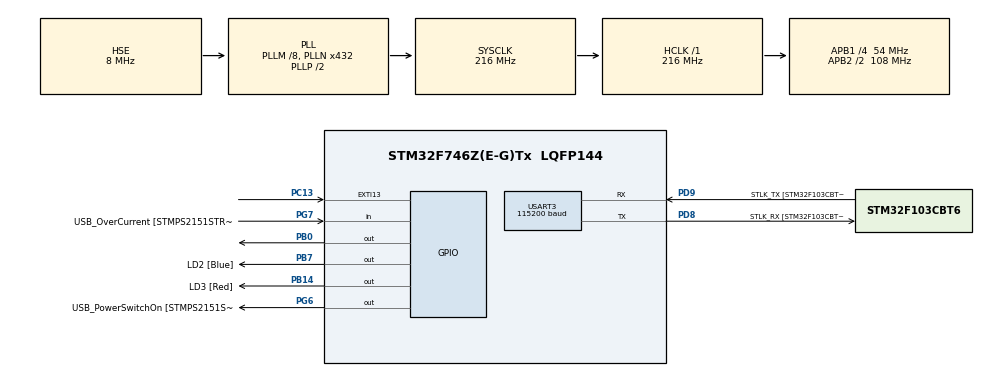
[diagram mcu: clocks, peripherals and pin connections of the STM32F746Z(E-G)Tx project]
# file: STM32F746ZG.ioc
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Mcu.Family=STM32F7
Mcu.Name=STM32F746Z(E-G)Tx
Mcu.Package=LQFP144
NVIC.EXTI15_10_IRQn=true\:3\:3\:true
NVIC.PriorityGroup=NVIC_PRIORITYGROUP_2
NVIC.USART3_IRQn=true\:0\:0\:false
PA1.GPIO_Label=RMII_REF_CK [LAN8742A-CZ-TR_REFCLK0]
PA1.Signal=ETH_REF_CLK
PA10.GPIO_Label=USB_ID
PA10.Signal=USB_OTG_FS_ID
PA11.GPIO_Label=USB_DM
PA11.Signal=USB_OTG_FS_DM
PA12.GPIO_Label=USB_DP
PA12.Signal=USB_OTG_FS_DP
PA13.GPIO_Label=TMS
PA13.Mode=Trace-Asynchronous_SW
PA13.Signal=SYS_JTMS-SWDIO
PA14.GPIO_Label=TCK
PA14.Mode=Trace-Asynchronous_SW
PA14.Signal=SYS_JTCK-SWCLK
PA2.GPIO_Label=RMII_MDIO [LAN8742A-CZ-TR_MDIO]
PA2.Signal=ETH_MDIO
PA7.GPIO_Label=RMII_CRS_DV [LAN8742A-CZ-TR_CRS_DV]
PA7.Signal=ETH_CRS_DV
PA8.GPIO_Label=USB_SOF [TP1]
PA8.Signal=USB_OTG_FS_SOF
PA9.GPIO_Label=USB_VBUS
PA9.Signal=USB_OTG_FS_VBUS
PB0.Signal=GPIO_Output
PB13.GPIO_Label=RMII_TXD1 [LAN8742A-CZ-TR_TXD1]
PB13.Signal=ETH_TXD1
PB14.GPIO_Label=LD3 [Red]
PB14.Signal=GPIO_Output
PB3.GPIO_Label=SW0
PB3.Mode=Trace-Asynchronous_SW
PB3.Signal=SYS_JTDO-SWO
PB7.GPIO_Label=LD2 [Blue]
PB7.Signal=GPIO_Output
PC1.GPIO_Label=RMII_MDC [LAN8742A-CZ-TR_MDC]
PC1.Signal=ETH_MDC
PC13.Signal=GPXTI13
PC14/OSC32_IN.Signal=RCC_OSC32_IN
PC15/OSC32_OUT.Signal=RCC_OSC32_OUT
PC4.GPIO_Label=RMII_RXD0 [LAN8742A-CZ-TR_RXD0]
PC4.Signal=ETH_RXD0
PC5.GPIO_Label=RMII_RXD1 [LAN8742A-CZ-TR_RXD1]
PC5.Signal=ETH_RXD1
PD8.GPIO_Label=STLK_RX [STM32F103CBT6_PA3]
PD8.Mode=Asynchronous
PD8.Signal=USART3_TX
PD9.GPIO_Label=STLK_TX [STM32F103CBT6_PA2]
PD9.Mode=Asynchronous
PD9.Signal=USART3_RX
PG11.GPIO_Label=RMII_TX_EN [LAN8742A-CZ-TR_TXEN]
PG11.Signal=ETH_TX_EN
PG13.GPIO_Label=RMII_TXD0 [LAN8742A-CZ-TR_TXD0]
PG13.Signal=ETH_TXD0
PG6.GPIO_Label=USB_PowerSwitchOn [STMPS2151STR_EN]
PG6.Signal=GPIO_Output
PG7.GPIO_Label=USB_OverCurrent [STMPS2151STR_FAULT]
PG7.Signal=GPIO_Input
PH0/OSC_IN.GPIO_Label=MCO [STM32F103CBT6_PA8]
PH0/OSC_IN.Mode=HSE-External-Oscillator
PH0/OSC_IN.Signal=RCC_OSC_IN
PH1/OSC_OUT.Mode=HSE-External-Oscillator
PH1/OSC_OUT.Signal=RCC_OSC_OUT
ProjectManager.TargetToolchain=MDK-ARM V5
RCC.48MHZClocksFreq_Value=24000000
RCC.AHBFreq_Value=216000000
RCC.APB1CLKDivider=RCC_HCLK_DIV4
RCC.APB1Freq_Value=54000000
RCC.APB1TimFreq_Value=108000000
RCC.APB2CLKDivider=RCC_HCLK_DIV2
RCC.APB2Freq_Value=108000000
RCC.APB2TimFreq_Value=216000000
RCC.CortexFreq_Value=216000000
RCC.HCLKFreq_Value=216000000
RCC.HSE_VALUE=8000000
RCC.HSI_VALUE=8000000
RCC.LSE_VALUE=32768
RCC.PLLM=8
RCC.PLLMUL=RCC_PLL_MUL9
RCC.PLLN=432
RCC.PLLSourceVirtual=RCC_PLLSOURCE_HSE
RCC.PRESCALERUSB=RCC_USBPLLCLK_DIV1_5
RCC.SYSCLKFreq_VALUE=216000000
RCC.SYSCLKSource=RCC_SYSCLKSOURCE_PLLCLK
RCC.SYSCLKSourceVirtual=RCC_SYSCLKSOURCE_PLLCLK
RCC.USBFreq_Value=216000000
RCC.VCOOutputFreq_Value=432000000
USART3.BaudRate=115200
USART3.OverSampling=UART_OVERSAMPLING_16
USART3.WordLength=UART_WORDLENGTH_8B
board=NUCLEO-F746ZG

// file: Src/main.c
/**
  ******************************************************************************
  * File Name          : main.c
  * Description        : Main program body
  ******************************************************************************
  *
  * COPYRIGHT(c) 2016 STMicroelectronics
  *
  * Redistribution and use in source and binary forms, with or without modification,
  * are permitted provided that the following conditions are met:
  *   1. Redistributions of source code must retain the above copyright notice,
  *      this list of conditions and the following disclaimer.
  *   2. Redistributions in binary form must reproduce the above copyright notice,
  *      this list of conditions and the following disclaimer in the documentation
  *      and/or other materials provided with the distribution.
  *   3. Neither the name of STMicroelectronics nor the names of its contributors
  *      may be used to endorse or promote products derived from this software
  *      without specific prior written permission.
  *
  * THIS SOFTWARE IS PROVIDED BY THE COPYRIGHT HOLDERS AND CONTRIBUTORS "AS IS"
  * AND ANY EXPRESS OR IMPLIED WARRANTIES, INCLUDING, BUT NOT LIMITED TO, THE
  * IMPLIED WARRANTIES OF MERCHANTABILITY AND FITNESS FOR A PARTICULAR PURPOSE ARE
  * DISCLAIMED. IN NO EVENT SHALL THE COPYRIGHT HOLDER OR CONTRIBUTORS BE LIABLE
  * FOR ANY DIRECT, INDIRECT, INCIDENTAL, SPECIAL, EXEMPLARY, OR CONSEQUENTIAL
  * DAMAGES (INCLUDING, BUT NOT LIMITED TO, PROCUREMENT OF SUBSTITUTE GOODS OR
  * SERVICES; LOSS OF USE, DATA, OR PROFITS; OR BUSINESS INTERRUPTION) HOWEVER
  * CAUSED AND ON ANY THEORY OF LIABILITY, WHETHER IN CONTRACT, STRICT LIABILITY,
  * OR TORT (INCLUDING NEGLIGENCE OR OTHERWISE) ARISING IN ANY WAY OUT OF THE USE
  * OF THIS SOFTWARE, EVEN IF ADVISED OF THE POSSIBILITY OF SUCH DAMAGE.
  *
  ******************************************************************************
  */
#include "stm32f7xx_hal.h"
#include "usart.h"
#include "gpio.h"

/* USER CODE BEGIN PV */
/* Private variables ---------------------------------------------------------*/

/* USER CODE END PV */

void SystemClock_Config(void);

/* USER CODE BEGIN PFP */
/* Private function prototypes -----------------------------------------------*/

/* USER CODE END PFP */

/* USER CODE BEGIN 0 */
volatile uint8_t pressed = 0;
uint8_t txBuffer[] = "This is a test program! \r\n\t\t--by Fengzi\r\n";
uint8_t txBuffer2[] = "User key is pressed!\r\n";

/* USER CODE END 0 */

int main(void)
{

  /* MCU Configuration----------------------------------------------------------*/

  /* Reset of all peripherals, Initializes the Flash interface and the Systick. */
  HAL_Init();

  /* Configure the system clock */
  SystemClock_Config();

  /* Initialize all configured peripherals */
  MX_GPIO_Init();
  MX_USART3_UART_Init();

  /* USER CODE BEGIN 2 */
	HAL_GPIO_WritePin(LD2_GPIO_Port,LD2_Pin,GPIO_PIN_SET);
//	HAL_GPIO_WritePin(LD3_GPIO_Port,LD3_Pin,GPIO_PIN_SET);

	HAL_UART_Transmit(&huart3,txBuffer,sizeof(txBuffer),0xffff);

  /* USER CODE END 2 */

  /* Infinite loop */
  while (1)
  {

  /* USER CODE BEGIN 3 */
		if(pressed)
		{
			HAL_UART_Transmit(&huart3,txBuffer2,sizeof(txBuffer2),0xffff);

			HAL_GPIO_TogglePin(LD2_GPIO_Port,LD2_Pin);
			HAL_GPIO_TogglePin(LD3_GPIO_Port,LD3_Pin);

			pressed = 0;
		}
		HAL_Delay(500);

  }
  /* USER CODE END 3 */

}

/** System Clock Configuration
*/
void SystemClock_Config(void)
{

  RCC_OscInitTypeDef RCC_OscInitStruct;
  RCC_ClkInitTypeDef RCC_ClkInitStruct;
  RCC_PeriphCLKInitTypeDef PeriphClkInitStruct;

  __PWR_CLK_ENABLE();

  __HAL_PWR_VOLTAGESCALING_CONFIG(PWR_REGULATOR_VOLTAGE_SCALE1);

  RCC_OscInitStruct.OscillatorType = RCC_OSCILLATORTYPE_HSE;
  RCC_OscInitStruct.HSEState = RCC_HSE_ON;
  RCC_OscInitStruct.PLL.PLLState = RCC_PLL_ON;
  RCC_OscInitStruct.PLL.PLLSource = RCC_PLLSOURCE_HSE;
  RCC_OscInitStruct.PLL.PLLM = 8;
  RCC_OscInitStruct.PLL.PLLN = 432;
  RCC_OscInitStruct.PLL.PLLP = RCC_PLLP_DIV2;
  RCC_OscInitStruct.PLL.PLLQ = 2;
  HAL_RCC_OscConfig(&RCC_OscInitStruct);

  HAL_PWREx_ActivateOverDrive();

  RCC_ClkInitStruct.ClockType = RCC_CLOCKTYPE_HCLK|RCC_CLOCKTYPE_SYSCLK
                              |RCC_CLOCKTYPE_PCLK1|RCC_CLOCKTYPE_PCLK2;
  RCC_ClkInitStruct.SYSCLKSource = RCC_SYSCLKSOURCE_PLLCLK;
  RCC_ClkInitStruct.AHBCLKDivider = RCC_SYSCLK_DIV1;
  RCC_ClkInitStruct.APB1CLKDivider = RCC_HCLK_DIV4;
  RCC_ClkInitStruct.APB2CLKDivider = RCC_HCLK_DIV2;
  HAL_RCC_ClockConfig(&RCC_ClkInitStruct, FLASH_LATENCY_7);

  PeriphClkInitStruct.PeriphClockSelection = RCC_PERIPHCLK_USART3;
  PeriphClkInitStruct.Usart3ClockSelection = RCC_USART3CLKSOURCE_PCLK1;
  HAL_RCCEx_PeriphCLKConfig(&PeriphClkInitStruct);

  HAL_SYSTICK_Config(HAL_RCC_GetHCLKFreq()/1000);

  HAL_SYSTICK_CLKSourceConfig(SYSTICK_CLKSOURCE_HCLK);

  /* SysTick_IRQn interrupt configuration */
  HAL_NVIC_SetPriority(SysTick_IRQn, 0, 0);
}

/* USER CODE BEGIN 4 */
void HAL_GPIO_EXTI_Callback(uint16_t GPIO_Pin)
{
	if(HAL_GPIO_ReadPin(GPIOC,GPIO_Pin))
	{
		pressed = 1;
	}

}

/* USER CODE END 4 */

/************************ (C) COPYRIGHT STMicroelectronics *****END OF FILE****/
